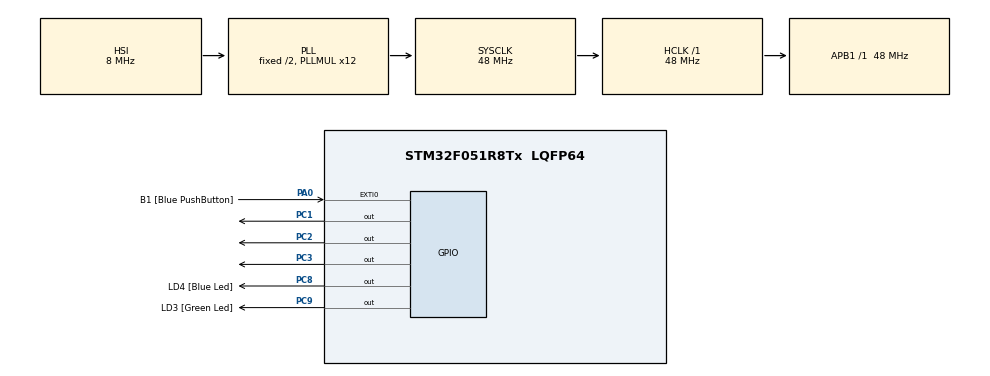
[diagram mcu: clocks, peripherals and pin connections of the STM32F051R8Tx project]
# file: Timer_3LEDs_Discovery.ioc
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Mcu.Family=STM32F0
Mcu.Name=STM32F051R8Tx
Mcu.Package=LQFP64
NVIC.TIM1_BRK_UP_TRG_COM_IRQn=true\:0\:0\:false\:false\:true\:true\:true\:true
NVIC.TIM2_IRQn=true\:0\:0\:false\:false\:true\:true\:true\:true
NVIC.TIM3_IRQn=true\:0\:0\:false\:false\:true\:true\:true\:true
PA0.GPIO_Label=B1 [Blue PushButton]
PA0.GPIO_ModeDefaultEXTI=GPIO_MODE_EVT_RISING
PA0.Signal=GPXTI0
PA13.GPIO_Label=SWDIO
PA13.Mode=Serial_Wire
PA13.Signal=SYS_SWDIO
PA14.GPIO_Label=SWCLK
PA14.Mode=Serial_Wire
PA14.Signal=SYS_SWCLK
PC1.Signal=GPIO_Output
PC2.Signal=GPIO_Output
PC3.Signal=GPIO_Output
PC8.GPIO_Label=LD4 [Blue Led]
PC8.Signal=GPIO_Output
PC9.GPIO_Label=LD3 [Green Led]
PC9.Signal=GPIO_Output
ProjectManager.HeapSize=0x200
ProjectManager.StackSize=0x400
ProjectManager.TargetToolchain=STM32CubeIDE
RCC.AHBFreq_Value=48000000
RCC.APB1Freq_Value=48000000
RCC.APB1TimFreq_Value=48000000
RCC.HCLKFreq_Value=48000000
RCC.PLLMUL=RCC_PLL_MUL12
RCC.SYSCLKFreq_VALUE=48000000
RCC.SYSCLKSource=RCC_SYSCLKSOURCE_PLLCLK
TIM1.Period=999
TIM1.Prescaler=47999
TIM2.Period=499
TIM2.Prescaler=47999
TIM3.Period=249
TIM3.Prescaler=47999
VP_TIM1_VS_ClockSourceINT.Mode=Internal
VP_TIM2_VS_ClockSourceINT.Mode=Internal
VP_TIM3_VS_ClockSourceINT.Mode=Internal
board=STM32F0DISCOVERY

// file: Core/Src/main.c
/* USER CODE BEGIN Header */
/**
  ******************************************************************************
  * @file           : main.c
  * @brief          : Main program body
  ******************************************************************************
  * @attention
  *
  * Copyright (c) 2025 STMicroelectronics.
  * All rights reserved.
  *
  * This software is licensed under terms that can be found in the LICENSE file
  * in the root directory of this software component.
  * If no LICENSE file comes with this software, it is provided AS-IS.
  *
  ******************************************************************************
  */
/* USER CODE END Header */
#include "main.h"

TIM_HandleTypeDef htim1;
TIM_HandleTypeDef htim2;
TIM_HandleTypeDef htim3;

void SystemClock_Config(void);
static void MX_GPIO_Init(void);
static void MX_TIM1_Init(void);
static void MX_TIM2_Init(void);
static void MX_TIM3_Init(void);

int main(void)
{

  /* MCU Configuration--------------------------------------------------------*/

  /* Reset of all peripherals, Initializes the Flash interface and the Systick. */
  HAL_Init();

  /* Configure the system clock */
  SystemClock_Config();

  /* Initialize all configured peripherals */
  MX_GPIO_Init();
  MX_TIM1_Init();
  MX_TIM2_Init();
  MX_TIM3_Init();
  /* USER CODE BEGIN 2 */

  //Chang

  HAL_TIM_Base_Start_IT(&htim1);
  HAL_TIM_Base_Start_IT(&htim2);
  HAL_TIM_Base_Start_IT(&htim3);
  /* USER CODE END 2 */

  /* Infinite loop */
  while (1)
  {

  }
}

void SystemClock_Config(void)
{
  RCC_OscInitTypeDef RCC_OscInitStruct = {0};
  RCC_ClkInitTypeDef RCC_ClkInitStruct = {0};

  /** Initializes the RCC Oscillators according to the specified parameters
  * in the RCC_OscInitTypeDef structure.
  */
  RCC_OscInitStruct.OscillatorType = RCC_OSCILLATORTYPE_HSI;
  RCC_OscInitStruct.HSIState = RCC_HSI_ON;
  RCC_OscInitStruct.HSICalibrationValue = RCC_HSICALIBRATION_DEFAULT;
  RCC_OscInitStruct.PLL.PLLState = RCC_PLL_ON;
  RCC_OscInitStruct.PLL.PLLSource = RCC_PLLSOURCE_HSI;
  RCC_OscInitStruct.PLL.PLLMUL = RCC_PLL_MUL12;
  RCC_OscInitStruct.PLL.PREDIV = RCC_PREDIV_DIV1;
  if (HAL_RCC_OscConfig(&RCC_OscInitStruct) != HAL_OK)
  {
    Error_Handler();
  }

  /** Initializes the CPU, AHB and APB buses clocks
  */
  RCC_ClkInitStruct.ClockType = RCC_CLOCKTYPE_HCLK|RCC_CLOCKTYPE_SYSCLK
                              |RCC_CLOCKTYPE_PCLK1;
  RCC_ClkInitStruct.SYSCLKSource = RCC_SYSCLKSOURCE_PLLCLK;
  RCC_ClkInitStruct.AHBCLKDivider = RCC_SYSCLK_DIV1;
  RCC_ClkInitStruct.APB1CLKDivider = RCC_HCLK_DIV1;

  if (HAL_RCC_ClockConfig(&RCC_ClkInitStruct, FLASH_LATENCY_1) != HAL_OK)
  {
    Error_Handler();
  }
}

static void MX_TIM1_Init(void)
{

  TIM_ClockConfigTypeDef sClockSourceConfig = {0};
  TIM_MasterConfigTypeDef sMasterConfig = {0};

  htim1.Instance = TIM1;
  htim1.Init.Prescaler = 47999;
  htim1.Init.CounterMode = TIM_COUNTERMODE_UP;
  htim1.Init.Period = 999;
  htim1.Init.ClockDivision = TIM_CLOCKDIVISION_DIV1;
  htim1.Init.RepetitionCounter = 0;
  htim1.Init.AutoReloadPreload = TIM_AUTORELOAD_PRELOAD_DISABLE;
  if (HAL_TIM_Base_Init(&htim1) != HAL_OK)
  {
    Error_Handler();
  }
  sClockSourceConfig.ClockSource = TIM_CLOCKSOURCE_INTERNAL;
  if (HAL_TIM_ConfigClockSource(&htim1, &sClockSourceConfig) != HAL_OK)
  {
    Error_Handler();
  }
  sMasterConfig.MasterOutputTrigger = TIM_TRGO_RESET;
  sMasterConfig.MasterSlaveMode = TIM_MASTERSLAVEMODE_DISABLE;
  if (HAL_TIMEx_MasterConfigSynchronization(&htim1, &sMasterConfig) != HAL_OK)
  {
    Error_Handler();
  }

}

static void MX_TIM2_Init(void)
{

  TIM_ClockConfigTypeDef sClockSourceConfig = {0};
  TIM_MasterConfigTypeDef sMasterConfig = {0};

  htim2.Instance = TIM2;
  htim2.Init.Prescaler = 47999;
  htim2.Init.CounterMode = TIM_COUNTERMODE_UP;
  htim2.Init.Period = 499;
  htim2.Init.ClockDivision = TIM_CLOCKDIVISION_DIV1;
  htim2.Init.AutoReloadPreload = TIM_AUTORELOAD_PRELOAD_DISABLE;
  if (HAL_TIM_Base_Init(&htim2) != HAL_OK)
  {
    Error_Handler();
  }
  sClockSourceConfig.ClockSource = TIM_CLOCKSOURCE_INTERNAL;
  if (HAL_TIM_ConfigClockSource(&htim2, &sClockSourceConfig) != HAL_OK)
  {
    Error_Handler();
  }
  sMasterConfig.MasterOutputTrigger = TIM_TRGO_RESET;
  sMasterConfig.MasterSlaveMode = TIM_MASTERSLAVEMODE_DISABLE;
  if (HAL_TIMEx_MasterConfigSynchronization(&htim2, &sMasterConfig) != HAL_OK)
  {
    Error_Handler();
  }

}

static void MX_TIM3_Init(void)
{

  TIM_ClockConfigTypeDef sClockSourceConfig = {0};
  TIM_MasterConfigTypeDef sMasterConfig = {0};

  htim3.Instance = TIM3;
  htim3.Init.Prescaler = 47999;
  htim3.Init.CounterMode = TIM_COUNTERMODE_UP;
  htim3.Init.Period = 249;
  htim3.Init.ClockDivision = TIM_CLOCKDIVISION_DIV1;
  htim3.Init.AutoReloadPreload = TIM_AUTORELOAD_PRELOAD_DISABLE;
  if (HAL_TIM_Base_Init(&htim3) != HAL_OK)
  {
    Error_Handler();
  }
  sClockSourceConfig.ClockSource = TIM_CLOCKSOURCE_INTERNAL;
  if (HAL_TIM_ConfigClockSource(&htim3, &sClockSourceConfig) != HAL_OK)
  {
    Error_Handler();
  }
  sMasterConfig.MasterOutputTrigger = TIM_TRGO_RESET;
  sMasterConfig.MasterSlaveMode = TIM_MASTERSLAVEMODE_DISABLE;
  if (HAL_TIMEx_MasterConfigSynchronization(&htim3, &sMasterConfig) != HAL_OK)
  {
    Error_Handler();
  }

}

static void MX_GPIO_Init(void)
{
  GPIO_InitTypeDef GPIO_InitStruct = {0};

  /* GPIO Ports Clock Enable */
  __HAL_RCC_GPIOC_CLK_ENABLE();
  __HAL_RCC_GPIOA_CLK_ENABLE();

  /*Configure GPIO pin Output Level */
  HAL_GPIO_WritePin(GPIOC, GPIO_PIN_1|GPIO_PIN_2|GPIO_PIN_3|LD4_Pin
                          |LD3_Pin, GPIO_PIN_RESET);

  /*Configure GPIO pins : PC1 PC2 PC3 LD4_Pin
                           LD3_Pin */
  GPIO_InitStruct.Pin = GPIO_PIN_1|GPIO_PIN_2|GPIO_PIN_3|LD4_Pin
                          |LD3_Pin;
  GPIO_InitStruct.Mode = GPIO_MODE_OUTPUT_PP;
  GPIO_InitStruct.Pull = GPIO_NOPULL;
  GPIO_InitStruct.Speed = GPIO_SPEED_FREQ_LOW;
  HAL_GPIO_Init(GPIOC, &GPIO_InitStruct);

  /*Configure GPIO pin : B1_Pin */
  GPIO_InitStruct.Pin = B1_Pin;
  GPIO_InitStruct.Mode = GPIO_MODE_EVT_RISING;
  GPIO_InitStruct.Pull = GPIO_NOPULL;
  HAL_GPIO_Init(B1_GPIO_Port, &GPIO_InitStruct);

}

/* USER CODE BEGIN 4 */
void HAL_TIM_PeriodElapsedCallback(TIM_HandleTypeDef *htim)
{
  if(htim->Instance == TIM1)
  {
    /* Toggle LED */
    HAL_GPIO_TogglePin(GPIOC, GPIO_PIN_1);
  }
  else if(htim->Instance == TIM2)
     {
      /* Toggle LED */
      HAL_GPIO_TogglePin(GPIOC, GPIO_PIN_2);
     }
  else if(htim->Instance == TIM3)
      {
        /* Toggle LED */
        HAL_GPIO_TogglePin(GPIOC, GPIO_PIN_3);
      }

}
/* USER CODE END 4 */

void Error_Handler(void)
{
  __disable_irq();
  while (1)
  {
  }
}
